AUTOSAR XML (schema 314)
package /ComponentType
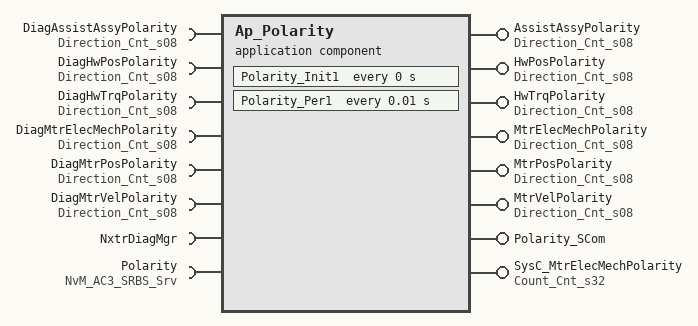
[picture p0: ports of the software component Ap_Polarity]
  application software component type Ap_Polarity
    8 x provide port:
      AssistAssyPolarity: unqueued-sender-com-spec{data-element=Cnt_s08, can-invalidate=false, init-value=D_ZERO_CNT_S8}, provided-interface=Direction_Cnt_s08
      HwPosPolarity: unqueued-sender-com-spec{data-element=Cnt_s08, can-invalidate=false, init-value=D_ZERO_CNT_S8}, provided-interface=Direction_Cnt_s08
      HwTrqPolarity: unqueued-sender-com-spec{data-element=Cnt_s08, can-invalidate=false, init-value=D_ZERO_CNT_S8}, provided-interface=Direction_Cnt_s08
      MtrElecMechPolarity: unqueued-sender-com-spec{data-element=Cnt_s08, can-invalidate=false, init-value=D_ZERO_CNT_S8}, provided-interface=Direction_Cnt_s08
      MtrPosPolarity: unqueued-sender-com-spec{data-element=Cnt_s08, can-invalidate=false, init-value=D_ZERO_CNT_S8}, provided-interface=Direction_Cnt_s08
      MtrVelPolarity: unqueued-sender-com-spec{data-element=Cnt_s08, can-invalidate=false, init-value=D_ZERO_CNT_S8}, provided-interface=Direction_Cnt_s08
      Polarity_SCom: provided-com-specs=[{operation=ReadPolarity, queue-length=1}, {operation=SetPolarity, queue-length=1}], provided-interface=Polarity_SCom
      SysC_MtrElecMechPolarity: unqueued-sender-com-spec{data-element=Cnt_s32, can-invalidate=false, init-value=D_ZERO_CNT_S32}, provided-interface=Count_Cnt_s32
    8 x require port:
      DiagAssistAssyPolarity: unqueued-receiver-com-spec{data-element=Cnt_s08, init-value=D_ZERO_CNT_S8}, required-interface=Direction_Cnt_s08
      DiagHwPosPolarity: unqueued-receiver-com-spec{data-element=Cnt_s08, init-value=D_ZERO_CNT_S8}, required-interface=Direction_Cnt_s08
      DiagHwTrqPolarity: unqueued-receiver-com-spec{data-element=Cnt_s08, init-value=D_ZERO_CNT_S8}, required-interface=Direction_Cnt_s08
      DiagMtrElecMechPolarity: unqueued-receiver-com-spec{data-element=Cnt_s08, init-value=D_ZERO_CNT_S8}, required-interface=Direction_Cnt_s08
      DiagMtrPosPolarity: unqueued-receiver-com-spec{data-element=Cnt_s08, init-value=D_ZERO_CNT_S8}, required-interface=Direction_Cnt_s08
      DiagMtrVelPolarity: unqueued-receiver-com-spec{data-element=Cnt_s08, init-value=D_ZERO_CNT_S8}, required-interface=Direction_Cnt_s08
      NxtrDiagMgr: required-com-specs=[GetNTCActive, GetNTCFailed, GetNTCStatus, SetNTCStatus], required-interface=NxtrDiagMgr
      Polarity: required-com-specs=[EraseBlock, GetErrorStatus, InvalidateNvBlock, ReadBlock, SetRamBlockStatus, WriteBlock], required-interface=NvM_AC3_SRBS_Srv
  internal behavior Ap_Polarity_InternalBehavior: component=Ap_Polarity
    timing event Polarity_Init1_InitEvent: start-on-event=Polarity_Init1, period=0
    timing event TMT_Polarity_Per1: start-on-event=Polarity_Per1, period=0.01
    operation invoked event OIT_Polarity_SCom_ReadPolarity_Polarity_SCom_ReadPolarity: start-on-event=Polarity_SCom_ReadPolarity, operation=Polarity_SCom.ReadPolarity
    operation invoked event OIT_Polarity_SCom_SetPolarity_Polarity_SCom_SetPolarity: start-on-event=Polarity_SCom_SetPolarity, operation=Polarity_SCom.SetPolarity
    per instance memory Polarity_Cnt_Str: type=Polarity_DataType, type-definition=/DataType/Polarity_DataType
    port-api-options:
      enable-take-address=false, indirect-api=false, port=AssistAssyPolarity
      enable-take-address=false, indirect-api=false, port=DiagAssistAssyPolarity
      enable-take-address=false, indirect-api=false, port=DiagHwPosPolarity
      enable-take-address=false, indirect-api=false, port=DiagHwTrqPolarity
      enable-take-address=false, indirect-api=false, port=DiagMtrElecMechPolarity
      enable-take-address=false, indirect-api=false, port=DiagMtrPosPolarity
      enable-take-address=false, indirect-api=false, port=DiagMtrVelPolarity
      enable-take-address=false, indirect-api=false, port=HwPosPolarity
      enable-take-address=false, indirect-api=false, port=HwTrqPolarity
      enable-take-address=false, indirect-api=false, port=MtrElecMechPolarity
      enable-take-address=false, indirect-api=false, port=MtrPosPolarity
      enable-take-address=false, indirect-api=false, port=MtrVelPolarity
      enable-take-address=false, indirect-api=false, port=NxtrDiagMgr
      enable-take-address=false, indirect-api=false, port=Polarity
      enable-take-address=false, indirect-api=false, port=Polarity_SCom
      enable-take-address=false, indirect-api=false, port=SysC_MtrElecMechPolarity
    4 x runnable:
      Polarity_Init1
        7 x data write access:
          WRITE_AssistAssyPolarity_Cnt_s08: data-element=AssistAssyPolarity.Cnt_s08
          WRITE_HwPosPolarity_Cnt_s08: data-element=HwPosPolarity.Cnt_s08
          WRITE_HwTrqPolarity_Cnt_s08: data-element=HwTrqPolarity.Cnt_s08
          WRITE_MtrElecMechPolarity_Cnt_s08: data-element=MtrElecMechPolarity.Cnt_s08
          WRITE_MtrPosPolarity_Cnt_s08: data-element=MtrPosPolarity.Cnt_s08
          WRITE_MtrVelPolarity_Cnt_s08: data-element=MtrVelPolarity.Cnt_s08
          WRITE_SysC_MtrElecMechPolarity_Cnt_s32: data-element=SysC_MtrElecMechPolarity.Cnt_s32
      Polarity_Per1
        6 x data read access:
          READ_DiagAssistAssyPolarity_Cnt_s08: data-element=DiagAssistAssyPolarity.Cnt_s08
          READ_DiagHwPosPolarity_Cnt_s08: data-element=DiagHwPosPolarity.Cnt_s08
          READ_DiagHwTrqPolarity_Cnt_s08: data-element=DiagHwTrqPolarity.Cnt_s08
          READ_DiagMtrElecMechPolarity_Cnt_s08: data-element=DiagMtrElecMechPolarity.Cnt_s08
          READ_DiagMtrPosPolarity_Cnt_s08: data-element=DiagMtrPosPolarity.Cnt_s08
          READ_DiagMtrVelPolarity_Cnt_s08: data-element=DiagMtrVelPolarity.Cnt_s08
        sync call SC_NxtrDiagMgr_SetNTCStatus: operation=NxtrDiagMgr.SetNTCStatus, timeout=0
      Polarity_SCom_ReadPolarity
      Polarity_SCom_SetPolarity
        7 x data send point:
          SEND_AssistAssyPolarity_Cnt_s08: data-element=AssistAssyPolarity.Cnt_s08
          SEND_HwPosPolarity_Cnt_s08: data-element=HwPosPolarity.Cnt_s08
          SEND_HwTrqPolarity_Cnt_s08: data-element=HwTrqPolarity.Cnt_s08
          SEND_MtrElecMechPolarity_Cnt_s08: data-element=MtrElecMechPolarity.Cnt_s08
          SEND_MtrPosPolarity_Cnt_s08: data-element=MtrPosPolarity.Cnt_s08
          SEND_MtrVelPolarity_Cnt_s08: data-element=MtrVelPolarity.Cnt_s08
          SEND_SysC_MtrElecMechPolarity_Cnt_s32: data-element=SysC_MtrElecMechPolarity.Cnt_s32
        sync call SC_Polarity_WriteBlock: operation=Polarity.WriteBlock, timeout=0
    service-needss:
      swc nv block needs PolarityBlock: n-data-sets=0, readonly=false, reliability=LOW, resistant-to-changed-sw=false, restore-at-start=false, write-only-once=false, writing-frequency=0, writing-priority=LOW, mirror-block=Polarity_Cnt_Str
  swc implementation Ap_Polarity_Implementation: behavior=Ap_Polarity_InternalBehavior
    code-descriptors:
      code Code: type=SRC
